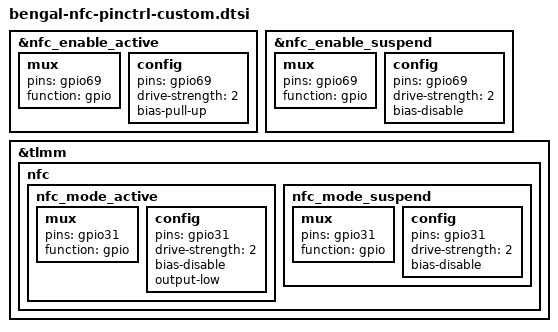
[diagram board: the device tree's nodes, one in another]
&nfc_enable_active {
			/* active state */
			mux {
				/* 69: VEN/Enable */
				pins = "gpio69";
				function = "gpio";
			};

			config {
				pins = "gpio69";
				drive-strength = <2>; /* 2 MA */
				bias-pull-up;
			};
};

&nfc_enable_suspend {
			/* sleep state */
			mux {
				/* 69: VEN/Enable */
				pins = "gpio69";
				function = "gpio";
			};

			config {
				pins = "gpio69";
				drive-strength = <2>; /* 2 MA */
				bias-disable;
			};
};

&tlmm {
	nfc {
		nfc_mode_active: nfc_mode_active {
			mux {
				/* 31: PN722x MODE (L=NFC Forum, H=EMVCo) */
				pins = "gpio31";
				function = "gpio";
			};

			config {
				pins = "gpio31";
				drive-strength = <2>; /* 2 MA */
				bias-disable;
				output-low;
			};
		};

		nfc_mode_suspend: nfc_mode_suspend {
			mux {
				pins = "gpio31";
				function = "gpio";
			};

			config {
				pins = "gpio31";
				drive-strength = <2>; /* 2 MA */
				bias-disable;
			};
		};
	};
};
